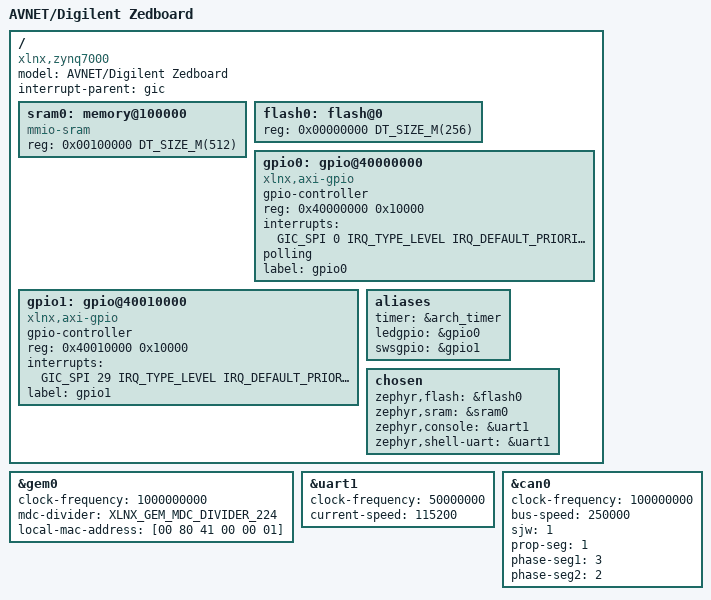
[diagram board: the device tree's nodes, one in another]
/*
 * Copyright (c) 2020, Weidmueller Interface GmbH & Co. KG
 * SPDX-License-Identifier: Apache-2.0
 */

/dts-v1/;

#include <xilinx/zynq7000.dtsi>
#include <dt-bindings/gpio/gpio.h>
#include <dt-bindings/ethernet/xlnx_gem.h>

/ {
	model = "AVNET/Digilent Zedboard";
	compatible = "xlnx,zynq7000";
	interrupt-parent = <&gic>;

	sram0: memory@100000 {
		compatible = "mmio-sram";
		reg = <0x00100000 DT_SIZE_M(512)>;
	};

	flash0: flash@0 {
		reg = <0x00000000 DT_SIZE_M(256)>;
	};

	gpio0: gpio@40000000 {
		gpio-controller;
		compatible = "xlnx,axi-gpio";
		reg = <0x40000000 0x10000>;
		interrupts = <GIC_SPI 0 IRQ_TYPE_LEVEL IRQ_DEFAULT_PRIORITY>;
		interrupt-names = "irq_0";
		polling;
		#gpio-cells = <2>;
		status = "disabled";
		label = "gpio0";
	};

	gpio1: gpio@40010000 {
		gpio-controller;
		compatible = "xlnx,axi-gpio";
		reg = <0x40010000 0x10000>;
		interrupts = <GIC_SPI 29 IRQ_TYPE_LEVEL
				IRQ_DEFAULT_PRIORITY>;
		interrupt-names = "irq_0";
		#gpio-cells = <2>;
		status = "disabled";
		label = "gpio1";
	};

	aliases {
		timer   = &arch_timer;
		ledgpio = &gpio0;
		swsgpio = &gpio1;
	};

	chosen {
		zephyr,flash      = &flash0;
		zephyr,sram       = &sram0;
		zephyr,console    = &uart1;
		zephyr,shell-uart = &uart1;
	};
};

&gem0 {
	status = "okay";
	clock-frequency = <1000000000>;
	mdc-divider = <XLNX_GEM_MDC_DIVIDER_224>;

	local-mac-address = [00 80 41 00 00 01];
};

&uart1 {
	status = "okay";
	clock-frequency = <50000000>;

	current-speed = <115200>;
};

&gpio0 {
	status = "okay";
};

&gpio1 {
	status = "okay";
};

&can0 {
	status = "okay";
	clock-frequency = <100000000>;

	bus-speed = <250000>;
	sjw = <1>;
	prop-seg = <1>;
	phase-seg1 = <3>;
	phase-seg2 = <2>;
};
